# MK30DZ10 register map
Vendor: Freescale Semiconductor, Inc.; Series: Kinetis_K; File version: 1.6
CPU: CM4 r0p1, little endian, no MPU, no FPU, VTOR, 4 interrupt priority bits
Registers are 32-bit, read-write, reset 0x0 unless marked. A register's access mark holds for its fields unless they carry their own. Offsets are from the block's base; [hi:lo] are bit positions.

## PMC — Mode Controller
Base 0x4007D000; register names take the prefix PMC_
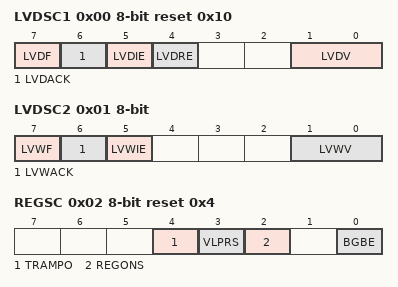
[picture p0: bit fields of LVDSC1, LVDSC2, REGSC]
0x00 LVDSC1 8-bit reset 0x10 — Low Voltage Detect Status and Control 1 Register
  [7] LVDF ro — Low-Voltage Detect Flag
    0=Low-voltage event not detected; 1=Low-voltage event detected
  [6] LVDACK wo — Low-Voltage Detect Acknowledge
  [5] LVDIE — Low-Voltage Detect Interrupt Enable
    0=Hardware interrupt disabled (use polling); 1=Request a hardware interrupt when LVDF = 1
  [4] LVDRE — Low-Voltage Detect Reset Enable
    0=LVDF does not generate hardware resets; 1=Force an MCU reset when LVDF = 1
  [1:0] LVDV — Low-Voltage Detect Voltage Select
    0=Low trip point selected (VLVD = VLVDL); 1=High trip point selected (VLVD = VLVDH)
0x01 LVDSC2 8-bit — Low Voltage Detect Status and Control 2 Register
  [7] LVWF ro — Low-Voltage Warning Flag
    0=Low-voltage warning event not detected; 1=Low-voltage warning event detected
  [6] LVWACK wo — Low-Voltage Warning Acknowledge
  [5] LVWIE — Low-Voltage Warning Interrupt Enable
    0=Hardware interrupt disabled (use polling); 1=Request a hardware interrupt when LVWF = 1
  [1:0] LVWV — Low-Voltage Warning Voltage Select
    0=Low trip point selected (VLVW = VLVW1H/L); 1=Mid 1 trip point selected (VLVW = VLVW2H/L); 2=Mid 2 trip point selected (VLVW = VLVW3H/L); 3=High trip point selected (VLVW = VLVW4H/L)
0x02 REGSC 8-bit reset 0x4 — Regulator Status and Control Register
  [4] TRAMPO — For devices with FlexNVM: Traditional RAM Power Option For devices with program flash only: Reserved
    0=For devices with FlexNVM: Traditional RAM not powered in VLLS2 For devices with program flash only: No effect; 1=For devices with FlexNVM: Traditional RAM powered in VLLS2 For devices with program flash only: No effect
  [3] VLPRS ro — Very Low Power Run Status
    0=MCU is not in VLPR mode; 1=MCU is in VLPR mode
  [2] REGONS ro — Regulator in Run Regulation Status
    0=Regulator is in stop regulation or in transition to/from it; 1=Regulator is in run regulation
  [0] BGBE — Bandgap Buffer Enable
    0=Bandgap buffer not enabled; 1=Bandgap buffer enabled

## MC — Mode Controller
Base 0x4007E000; register names take the prefix MC_
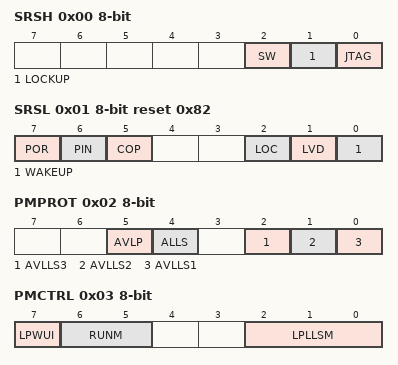
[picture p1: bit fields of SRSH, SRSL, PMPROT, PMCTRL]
0x00 SRSH 8-bit ro — System Reset Status Register High
  [2] SW — Software
    0=Reset not caused by software setting of SYSRESETREQ bit; 1=Reset caused by software setting of SYSRESETREQ bit
  [1] LOCKUP — Core Lock-up
    0=Reset not caused by core LOCKUP event; 1=Reset caused by core LOCKUP event
  [0] JTAG — JTAG generated reset
    0=Reset not caused by JTAG; 1=Reset caused by JTAG
0x01 SRSL 8-bit ro reset 0x82 — System Reset Status Register Low
  [7] POR — Power-on reset
    0=Reset not caused by POR; 1=Reset caused by POR
  [6] PIN — External reset pin
    0=Reset not caused by external reset pin; 1=Reset caused by external reset pin
  [5] COP — Computer Operating Properly (COP) Watchdog
    0=Reset not caused by COP timeout; 1=Reset caused by COP timeout
  [2] LOC — Loss-of-clock reset
    0=Reset not caused by a loss of external clock; 1=Reset caused by a loss of external clock
  [1] LVD — Low-voltage detect reset
    0=Reset not caused by LVD trip or POR; 1=Reset caused by LVD trip or POR
  [0] WAKEUP — Low-leakage wakeup reset
    0=Reset not caused by LLWU module wakeup source; 1=Reset caused by LLWU module wakeup source
0x02 PMPROT 8-bit — Power Mode Protection Register
  [5] AVLP — Allow very low power modes
    0=VLPR, VLPW, and VLPS are not allowed; 1=VLPR, VLPW, and VLPS are allowed
  [4] ALLS — Allow low leakage stop mode
    0=LLS is not allowed; 1=LLS is allowed
  [2] AVLLS3 — Allow Very Low Leakage Stop 3 Mode
    0=VLLS3 is not allowed; 1=VLLS3 is allowed
  [1] AVLLS2 — Allow very low leakage stop 2 mode
    0=VLLS2 is not allowed; 1=VLLS2 is allowed
  [0] AVLLS1 — Allow very low leakage stop 1 mode
    0=VLLS1 is not allowed; 1=VLLS1 is allowed
0x03 PMCTRL 8-bit — Power Mode Control Register
  [7] LPWUI — Low Power Wake Up on Interrupt
    0=The voltage regulator remains in stop regulation on an interrupt; 1=The voltage regulator exits stop regulation on an interrupt
  [6:5] RUNM — Run Mode Enable
    0=Normal run mode; 2=Very low power run mode
  [2:0] LPLLSM — Low Power, Low Leakage Stop Mode
    0=Normal stop; 2=Very low power stop (VLPS); 3=Low leakage stop (LLS); 5=Very low leakage stop 3 (VLLS3); 6=Very low leakage stop 2 (VLLS2); 7=Very low leakage stop 1 (VLLS1)

## Notices in the file
Redistribution and use in source and binary forms, with or without modification,
are permitted provided that the following conditions are met:
o Redistributions of source code must retain the above copyright notice, this list
of conditions and the following disclaimer.
o Redistributions in binary form must reproduce the above copyright notice, this
list of conditions and the following disclaimer in the documentation and/or
other materials provided with the distribution.
o Neither the name of Freescale Semiconductor, Inc. nor the names of its
contributors may be used to endorse or promote products derived from this
software without specific prior written permission.
THIS SOFTWARE IS PROVIDED BY THE COPYRIGHT HOLDERS AND CONTRIBUTORS "AS IS" AND
ANY EXPRESS OR IMPLIED WARRANTIES, INCLUDING, BUT NOT LIMITED TO, THE IMPLIED
WARRANTIES OF MERCHANTABILITY AND FITNESS FOR A PARTICULAR PURPOSE ARE
DISCLAIMED. IN NO EVENT SHALL THE COPYRIGHT HOLDER OR CONTRIBUTORS BE LIABLE FOR
ANY DIRECT, INDIRECT, INCIDENTAL, SPECIAL, EXEMPLARY, OR CONSEQUENTIAL DAMAGES
(INCLUDING, BUT NOT LIMITED TO, PROCUREMENT OF SUBSTITUTE GOODS OR SERVICES;
LOSS OF USE, DATA, OR PROFITS; OR BUSINESS INTERRUPTION) HOWEVER CAUSED AND ON
ANY THEORY OF LIABILITY, WHETHER IN CONTRACT, STRICT LIABILITY, OR TORT
(INCLUDING NEGLIGENCE OR OTHERWISE) ARISING IN ANY WAY OUT OF THE USE OF THIS
SOFTWARE, EVEN IF ADVISED OF THE POSSIBILITY OF SUCH DAMAGE.
